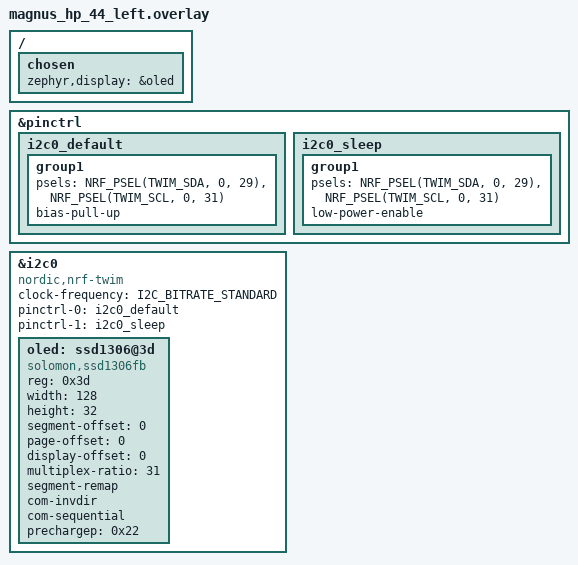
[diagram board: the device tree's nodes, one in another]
#include "magnus_hp_44.dtsi"

&pinctrl {
	i2c0_default: i2c0_default {
		group1 {
			psels = <NRF_PSEL(TWIM_SDA, 0, 29)>,
					<NRF_PSEL(TWIM_SCL, 0, 31)>;
			bias-pull-up;
		};
	};

	i2c0_sleep: i2c0_sleep {
		group1 {
			psels = <NRF_PSEL(TWIM_SDA, 0, 29)>,
					<NRF_PSEL(TWIM_SCL, 0, 31)>;
			low-power-enable;
		};
	};
};

&i2c0 {
	status = "okay";
	compatible = "nordic,nrf-twim";
	clock-frequency = <I2C_BITRATE_STANDARD>;
	pinctrl-0 = <&i2c0_default>;
	pinctrl-1 = <&i2c0_sleep>;
	pinctrl-names = "default", "sleep";

	oled: ssd1306@3d {
		compatible = "solomon,ssd1306fb";
		reg = <0x3d>;
		width = <128>;
		height = <32>;
		segment-offset = <0>;
		page-offset = <0>;
		display-offset = <0>;
		multiplex-ratio = <31>;
		segment-remap;
		com-invdir;
		com-sequential;
		prechargep = <0x22>;
	};
};

/ {
	chosen {
		zephyr,display = &oled;
	};
};
